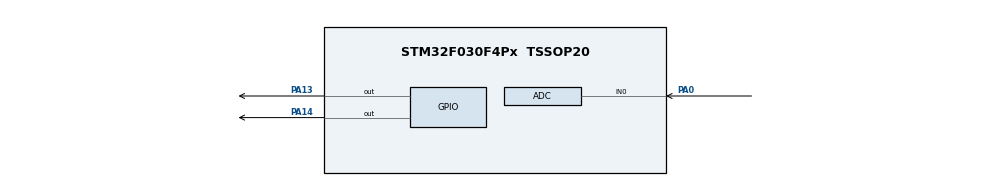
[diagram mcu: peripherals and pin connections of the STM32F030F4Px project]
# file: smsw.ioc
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FREERTOS.Tasks01=defaultTask,0,96,StartDefaultTask,Default,NULL,Dynamic,NULL,NULL
Mcu.Family=STM32F0
Mcu.Name=STM32F030F4Px
Mcu.Package=TSSOP20
PA0.Mode=IN0
PA0.Signal=ADC_IN0
PA13.Signal=GPIO_Output
PA14.Signal=GPIO_Output
ProjectManager.HeapSize=0x200
ProjectManager.StackSize=0x400
ProjectManager.TargetToolchain=MDK-ARM V5.27
VP_ADC_TempSens_Input.Mode=IN-TempSens
VP_FREERTOS_VS_CMSIS_V1.Mode=CMSIS_V1
board=custom

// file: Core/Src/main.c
/* USER CODE BEGIN Header */
/**
  ******************************************************************************
  * @file           : main.c
  * @brief          : Main program body
  ******************************************************************************
  * @attention
  *
  * <h2><center>&copy; Copyright (c) 2020 STMicroelectronics.
  * All rights reserved.</center></h2>
  *
  * This software component is licensed by ST under Ultimate Liberty license
  * SLA0044, the "License"; You may not use this file except in compliance with
  * the License. You may obtain a copy of the License at:
  *                             www.st.com/SLA0044
  *
  ******************************************************************************
  */
/* USER CODE END Header */
#include "main.h"
#include "cmsis_os.h"
#include "adc.h"
#include "gpio.h"

void SystemClock_Config(void);
void MX_FREERTOS_Init(void);

int main(void)
{

  /* MCU Configuration--------------------------------------------------------*/

  /* Reset of all peripherals, Initializes the Flash interface and the Systick. */
  HAL_Init();

  /* Configure the system clock */
  SystemClock_Config();

  /* Initialize all configured peripherals */
  MX_GPIO_Init();
  MX_ADC_Init();

  /* Call init function for freertos objects (in freertos.c) */
  MX_FREERTOS_Init();
  /* Start scheduler */
  osKernelStart();

  /* We should never get here as control is now taken by the scheduler */
  /* Infinite loop */
  while (1)
  {

  }
}

void SystemClock_Config(void)
{
  RCC_OscInitTypeDef RCC_OscInitStruct = {0};
  RCC_ClkInitTypeDef RCC_ClkInitStruct = {0};

  /** Initializes the RCC Oscillators according to the specified parameters
  * in the RCC_OscInitTypeDef structure.
  */
  RCC_OscInitStruct.OscillatorType = RCC_OSCILLATORTYPE_HSI|RCC_OSCILLATORTYPE_HSI14;
  RCC_OscInitStruct.HSIState = RCC_HSI_ON;
  RCC_OscInitStruct.HSI14State = RCC_HSI14_ON;
  RCC_OscInitStruct.HSICalibrationValue = RCC_HSICALIBRATION_DEFAULT;
  RCC_OscInitStruct.HSI14CalibrationValue = 16;
  RCC_OscInitStruct.PLL.PLLState = RCC_PLL_NONE;
  if (HAL_RCC_OscConfig(&RCC_OscInitStruct) != HAL_OK)
  {
    Error_Handler();
  }
  /** Initializes the CPU, AHB and APB buses clocks
  */
  RCC_ClkInitStruct.ClockType = RCC_CLOCKTYPE_HCLK|RCC_CLOCKTYPE_SYSCLK
                              |RCC_CLOCKTYPE_PCLK1;
  RCC_ClkInitStruct.SYSCLKSource = RCC_SYSCLKSOURCE_HSI;
  RCC_ClkInitStruct.AHBCLKDivider = RCC_SYSCLK_DIV1;
  RCC_ClkInitStruct.APB1CLKDivider = RCC_HCLK_DIV1;

  if (HAL_RCC_ClockConfig(&RCC_ClkInitStruct, FLASH_LATENCY_0) != HAL_OK)
  {
    Error_Handler();
  }
}

void Error_Handler(void)
{
}

/************************ (C) COPYRIGHT STMicroelectronics *****END OF FILE****/

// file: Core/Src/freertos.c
/* USER CODE BEGIN Header */
/**
  ******************************************************************************
  * File Name          : freertos.c
  * Description        : Code for freertos applications
  ******************************************************************************
  * @attention
  *
  * <h2><center>&copy; Copyright (c) 2020 STMicroelectronics.
  * All rights reserved.</center></h2>
  *
  * This software component is licensed by ST under Ultimate Liberty license
  * SLA0044, the "License"; You may not use this file except in compliance with
  * the License. You may obtain a copy of the License at:
  *                             www.st.com/SLA0044
  *
  ******************************************************************************
  */
/* USER CODE END Header */

#include "FreeRTOS.h"
#include "task.h"
#include "main.h"
#include "cmsis_os.h"

osThreadId defaultTaskHandle;

void StartDefaultTask(void const * argument);

void MX_FREERTOS_Init(void); /* (MISRA C 2004 rule 8.1) */

/* GetIdleTaskMemory prototype (linked to static allocation support) */
void vApplicationGetIdleTaskMemory( StaticTask_t **ppxIdleTaskTCBBuffer, StackType_t **ppxIdleTaskStackBuffer, uint32_t *pulIdleTaskStackSize );

/* USER CODE BEGIN GET_IDLE_TASK_MEMORY */
static StaticTask_t xIdleTaskTCBBuffer;
static StackType_t xIdleStack[configMINIMAL_STACK_SIZE];

void vApplicationGetIdleTaskMemory( StaticTask_t **ppxIdleTaskTCBBuffer, StackType_t **ppxIdleTaskStackBuffer, uint32_t *pulIdleTaskStackSize )
{
  *ppxIdleTaskTCBBuffer = &xIdleTaskTCBBuffer;
  *ppxIdleTaskStackBuffer = &xIdleStack[0];
  *pulIdleTaskStackSize = configMINIMAL_STACK_SIZE;
  /* place for user code */
}
/* USER CODE END GET_IDLE_TASK_MEMORY */

void MX_FREERTOS_Init(void) {

  /* Create the thread(s) */
  /* definition and creation of defaultTask */
  osThreadDef(defaultTask, StartDefaultTask, osPriorityNormal, 0, 96);
  defaultTaskHandle = osThreadCreate(osThread(defaultTask), NULL);

}

void StartDefaultTask(void const * argument)
{
  /* USER CODE BEGIN StartDefaultTask */
  /* Infinite loop */
  for(;;)
  {
		HAL_GPIO_WritePin(GPIOA,GPIO_PIN_14,GPIO_PIN_RESET);
		HAL_GPIO_WritePin(GPIOA,GPIO_PIN_13,GPIO_PIN_RESET);
    osDelay(1500);
		HAL_GPIO_WritePin(GPIOA,GPIO_PIN_14,GPIO_PIN_SET);
		HAL_GPIO_WritePin(GPIOA,GPIO_PIN_13,GPIO_PIN_SET);
    osDelay(1500);
  }
  /* USER CODE END StartDefaultTask */
}

/************************ (C) COPYRIGHT STMicroelectronics *****END OF FILE****/
